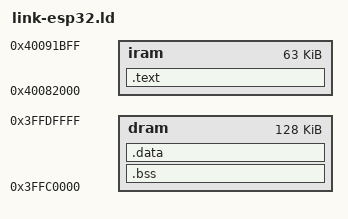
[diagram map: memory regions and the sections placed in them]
MEMORY {
  iram : org = 0x40082000, len = 0xFC00
  dram : org = 0x3ffc0000, len = 0x20000
}

ENTRY(_start)

SECTIONS {
  .text : ALIGN(4) {
    *(.literal)
    *(.text .text.*)
  } > iram

  .bss : ALIGN(4) {
     _bss_start = ABSOLUTE(.);
    *(.bss)
	_bss_end = ABSOLUTE(.);
  } > dram

  .data : ALIGN(4) {
    *(.data)
    *(.rodata .rodata.*)
  } > dram
}

